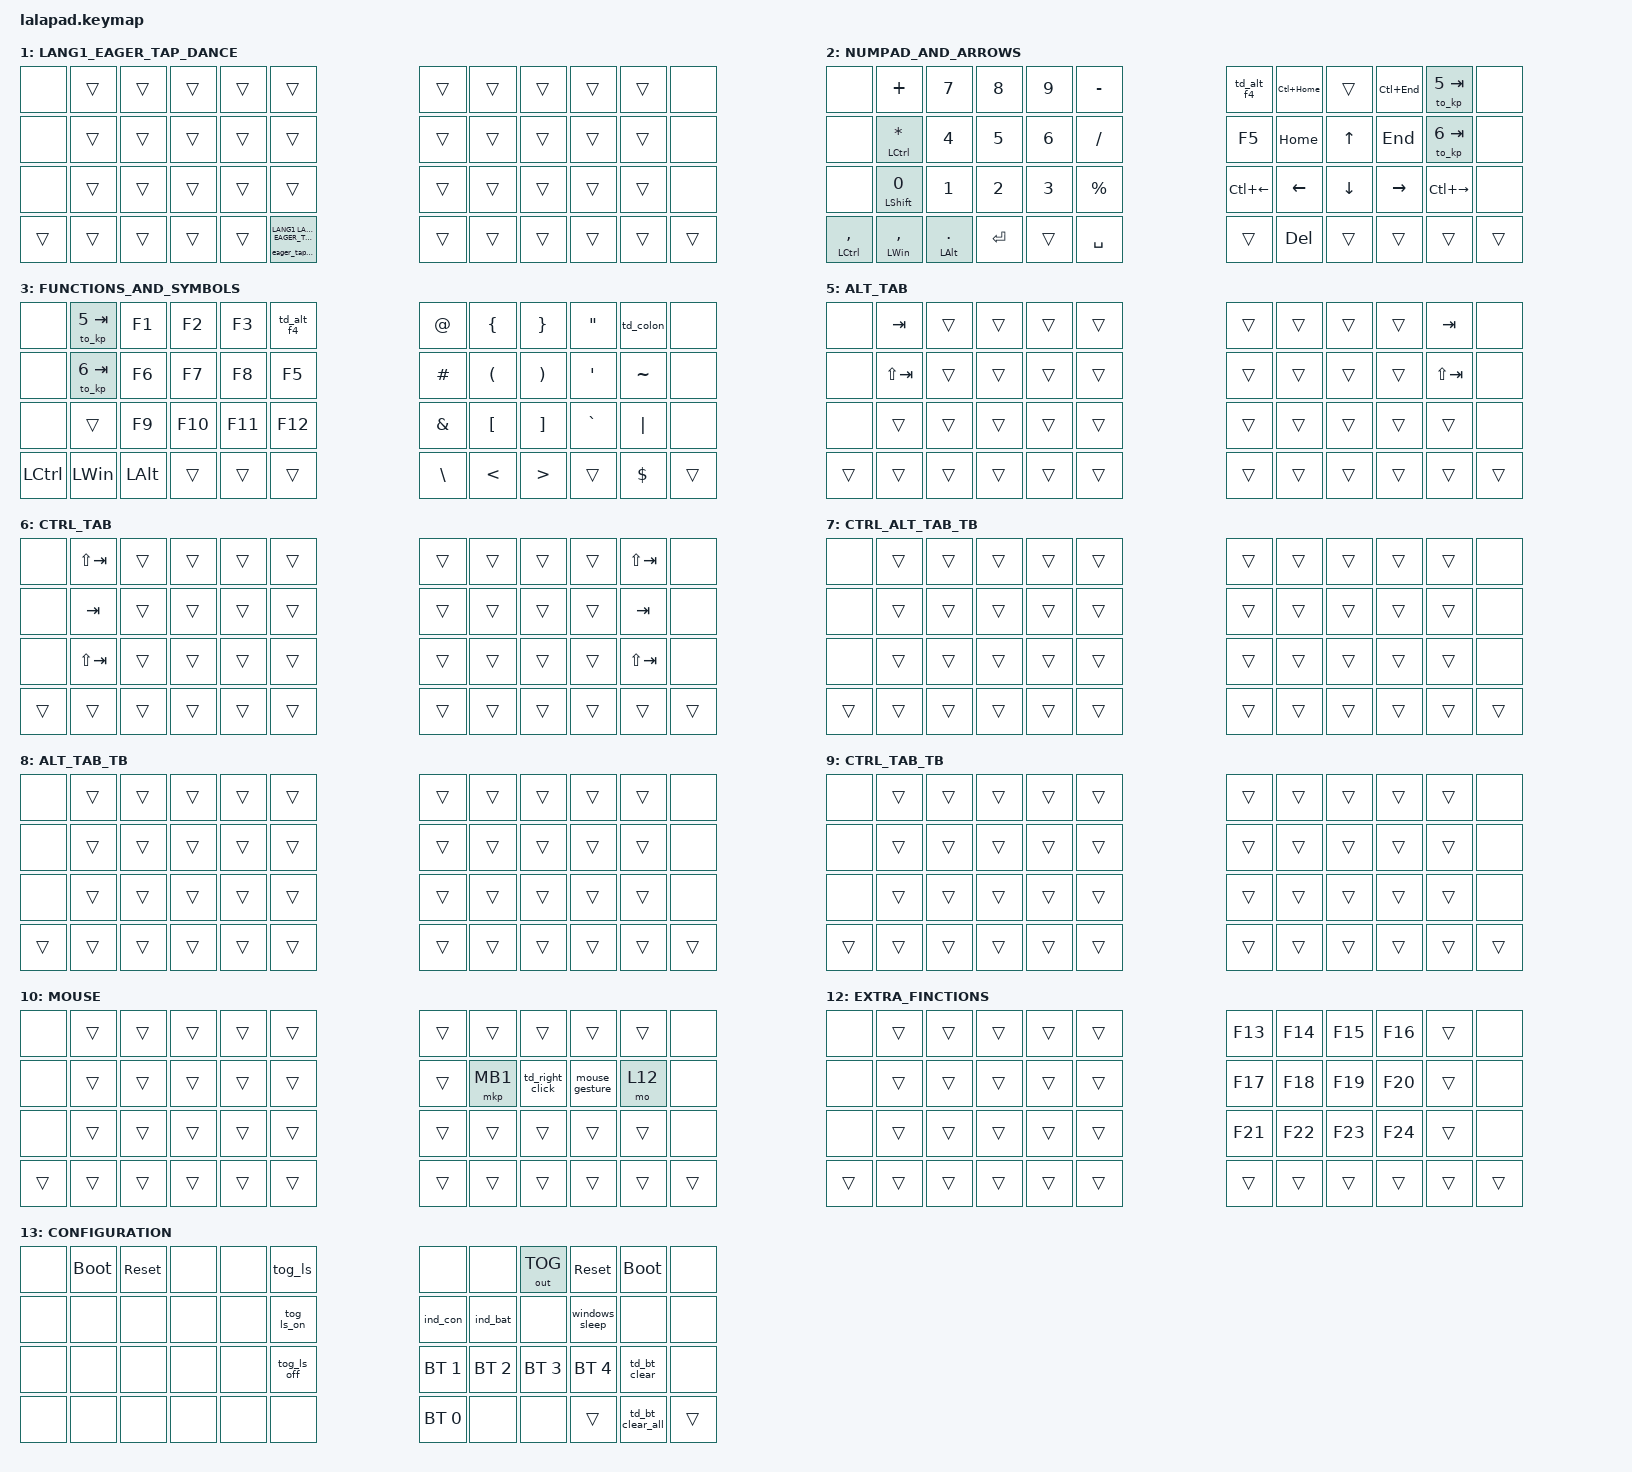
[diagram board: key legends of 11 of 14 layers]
#define ZMK_POINTING_DEFAULT_SCRL_VAL 1000

// #define ZMK_POINTING_DEFAULT_MOVE_VAL 700

#include <input/processors.dtsi>
#include <dt-bindings/zmk/input_transform.h>
#include <zephyr/dt-bindings/input/input-event-codes.h>
#include <behaviors/rgbled_widget.dtsi>
#include <input/processors/report_rate_limit.dtsi>
// #include <input/processors/sensor_rotation.dtsi>

#include <behaviors.dtsi>
#include <dt-bindings/zmk/bt.h>
#include <dt-bindings/zmk/keys.h>
#include <dt-bindings/zmk/outputs.h>
#include <dt-bindings/zmk/pointing.h>

// #include <layout_shift.dtsi>
#include <layout_shift_kp_override.dtsi>

#include <mouse-gesture.dtsi>

#define DEFAULT 0
#define LANG1_EAGER_TAP_DANCE 1
#define NUMPAD_AND_ARROWS 2
#define FUNCTIONS_AND_SYMBOLS 3
#define MISC 4
#define ALT_TAB 5
#define CTRL_TAB 6
#define CTRL_ALT_TAB_TB 7
#define ALT_TAB_TB 8
#define CTRL_TAB_TB 9
#define MOUSE 10
#define MEDIA 11
#define EXTRA_FINCTIONS 12
#define CONFIGURATION 13

&mt {
    tapping-term-ms = <200>;
    quick-tap-ms = <250>;
    flavor = "balanced";
};

&lt {
    tapping-term-ms = <200>;
    quick-tap-ms = <250>;
    flavor = "balanced";
};

&sk { release-after-ms = <700>; };

&sl { release-after-ms = <1000>; };

&zip_temp_layer {
    require-prior-idle-ms = <200>;
    excluded-positions = <
        18 // J
        19 // K
        20 // L
        21 // ;
        22 // Z
        // 31 // .
        // 32 // ,
        // 33 // /
        34 // Ctrl
        42
    >;
};

&mkp_input_listener { input-processors = <&zip_temp_layer MOUSE 10000>; };

&zip_mouse_gesture {
    stroke-size = <150>;
    enable-eager-mode;

    history_back {
        pattern = <GESTURE_RIGHT>;
        bindings = <&kp LA(LEFT)>;
    };

    history_forward {
        pattern = <GESTURE_LEFT>;
        bindings = <&kp LA(RIGHT)>;
    };

    close_tab {
        pattern = <GESTURE_DOWN GESTURE_RIGHT>;
        bindings = <&kp LC(W)>;
    };

    new_tab {
        pattern = <GESTURE_DOWN GESTURE_LEFT>;
        bindings = <&kp LC(T)>;
    };

    app_switcher {
        pattern = <GESTURE_DOWN GESTURE_UP>;
        bindings = <&kp LG(TAB)>;
    };

    virtual_desktop_prev {
        pattern = <GESTURE_LEFT GESTURE_DOWN>;
        bindings = <&kp LG(LC(LEFT))>;
    };

    virtual_desktop_next {
        pattern = <GESTURE_RIGHT GESTURE_DOWN>;
        bindings = <&kp LG(LC(RIGHT))>;
    };

    // left {
    //     gesture = <GESTURE_LEFT>;
    //     bindings = <&kp LEFT>;
    // };
    // right {
    //     gesture = <GESTURE_RIGHT>;
    //     bindings = <&kp RIGHT>;
    // };
    // up {
    //     gesture = <GESTURE_UP>;
    //     bindings = <&kp UP>;
    // };
    // down {
    //     gesture = <GESTURE_DOWN>;
    //     bindings = <&kp DOWN>;
    // };
};

// &sensor_rotation {
//     rotation-angle = <30>;
// };

// cirque trackpad input&layer control

&glidepoint_listener_R {
    input-processors =
        <&zip_report_rate_limit 15>,
        <&zip_xy_transform INPUT_TRANSFORM_X_INVERT>,
        // <&sensor_rotation>,
        <&zip_xy_scaler 4 1>,
        <&zip_mouse_gesture>,
        <&zip_temp_layer MOUSE 10000>;

    auto-mouse-layer {
        layers = <DEFAULT MOUSE>;
        input-processors = <&zip_temp_layer MOUSE 10000>;
        process-next;
    };

    scroller {
        layers = <FUNCTIONS_AND_SYMBOLS MISC EXTRA_FINCTIONS MEDIA>;
        input-processors =
            <&zip_xy_to_scroll_mapper>,
            <&zip_scroll_transform (INPUT_TRANSFORM_XY_SWAP | INPUT_TRANSFORM_Y_INVERT)>,
            <&zip_scroll_scaler 1 8>;
    };

    disable-scroll-x {
        layers = <MISC MEDIA>;
        input-processors = <&wheel_x_scaler 0 1>;
        process-next;
    };
};

/ {
    input_processors {
        wheel_x_scaler: wheel_x_scaler {
            compatible = "zmk,input-processor-scaler";
            #input-processor-cells = <2>;
            type = <INPUT_EV_REL>;
            codes = <INPUT_REL_HWHEEL>;
            track-remainders;
        };
    };

    layer_listeners {
        compatible = "zmk,layer-listeners";

        release_alt {
            layers = <ALT_TAB ALT_TAB_TB>;
            bindings = <&kt_on LEFT_ALT &kt_off LEFT_ALT>;
        };

        release_ctrl {
            layers = <CTRL_TAB CTRL_TAB_TB>;
            bindings = <&kt_on LCTRL &kt_off LCTRL>;
        };

        // AML_indicator {
        //     layers = <MOUSE>;
        //     bindings = <&kp LS(LA(LC(LG(H)))) &kp LS(LA(LC(LG(H))))>;
        // };
        // AML {
        //     layers = <MOUSE>;
        //     bindings = <&to MOUSE &none>;
        // };
    };

    combos {
        compatible = "zmk,combos";

        eq {
            bindings = <&kp EQUAL>;
            key-positions = <0 1>;
            layers = <2>;
        };

        hat {
            bindings = <&kp CARET>;
            key-positions = <10 11>;
            layers = <2>;
        };

        middle_click {
            bindings = <&mkp MCLK>;
            key-positions = <18 19>;
            layers = <10>;
        };

        shift_middle_click {
            bindings = <&mkp_with_mod LEFT_SHIFT MCLK>;
            key-positions = <19 20>;
            layers = <10>;
        };

        Escape {
            bindings = <&kp ESCAPE>;
            key-positions = <0 1>;
            layers = <0>;
            require-prior-idle-ms = <400>;
        };

        caps_word {
            bindings = <&caps_word>;
            key-positions = <22 33>;
            layers = <0>;
            require-prior-idle-ms = <400>;
        };

        dot_slash_backslash {
            bindings = <&kp BACKSLASH>;
            key-positions = <33 32>;
            layers = <0>;
            require-prior-idle-ms = <400>;
        };

        Ctrl_A {
            bindings = <&kp LC(A)>;
            key-positions = <10 11>;
            layers = <0>;
            require-prior-idle-ms = <400>;
        };

        Ctrl_W {
            bindings = <&kp LC(W)>;
            key-positions = <1 2>;
            layers = <0>;
            require-prior-idle-ms = <400>;
        };

        Ctrl_R {
            bindings = <&kp LC(R)>;
            key-positions = <2 3>;
            layers = <0>;
            require-prior-idle-ms = <400>;
        };

        Ctrl_T {
            bindings = <&kp LC(T)>;
            key-positions = <3 4>;
            layers = <0>;
            require-prior-idle-ms = <400>;
        };

        Ctrl_Z {
            bindings = <&kp LC(Z)>;
            key-positions = <23 22>;
            layers = <0>;
            require-prior-idle-ms = <400>;
        };

        Ctrl_X {
            bindings = <&kp LC(X)>;
            key-positions = <23 24>;
            layers = <0>;
            require-prior-idle-ms = <400>;
        };

        Ctrl_C {
            bindings = <&kp LC(C)>;
            key-positions = <24 25>;
            layers = <0>;
            require-prior-idle-ms = <400>;
        };

        Ctrl_V {
            bindings = <&kp LC(V)>;
            key-positions = <25 26>;
            layers = <0>;
            require-prior-idle-ms = <400>;
        };

        Ctrl_N {
            bindings = <&kp LC(N)>;
            key-positions = <29 30>;
            layers = <0>;
            require-prior-idle-ms = <400>;
        };

        Ctrl_S {
            bindings = <&kp LC(S)>;
            key-positions = <11 12>;
            layers = <0>;
            require-prior-idle-ms = <400>;
        };

        Ctrl_F {
            bindings = <&kp LC(F)>;
            key-positions = <13 14>;
            layers = <0>;
            require-prior-idle-ms = <400>;
        };
    };

    macros {
        /omit-if-no-ref/

        exit_AML: exit_AML {
            compatible = "zmk,behavior-macro";
            wait-ms = <0>;
            tap-ms = <0>;
            #binding-cells = <0>;
            bindings = <&tog_off 10>;
        };

        /omit-if-no-ref/

        kp_exit_AML: kp_exit_AML {
            compatible = "zmk,behavior-macro-one-param";
            wait-ms = <0>;
            tap-ms = <0>;
            #binding-cells = <1>;
            bindings = <&macro_param_1to1 &kp MACRO_PLACEHOLDER &exit_AML>;
        };

        /omit-if-no-ref/

        mod_exit_AML: mod_exit_AML {
            compatible = "zmk,behavior-macro-one-param";
            wait-ms = <0>;
            tap-ms = <0>;
            #binding-cells = <1>;
            bindings =
                <&macro_press>,
                <&macro_param_1to1 &kp MACRO_PLACEHOLDER>,
                <&macro_tap>,
                <&exit_AML>,
                <&macro_pause_for_release>,
                <&macro_release>,
                <&macro_param_1to1 &kp MACRO_PLACEHOLDER>;
        };

        /omit-if-no-ref/

        mkp_exit_AML: mkp_exit_AML {
            compatible = "zmk,behavior-macro-one-param";
            #binding-cells = <1>;
            bindings =
                <&macro_press>,
                <&macro_param_1to1 &mkp MACRO_PLACEHOLDER>,
                <&macro_pause_for_release>,
                <&macro_release>,
                <&macro_param_1to1 &mkp MACRO_PLACEHOLDER>,
                <&macro_tap>,
                <&sl 10>;
        };

        /omit-if-no-ref/

        mo_exit_AML: mo_exit_AML {
            compatible = "zmk,behavior-macro-one-param";
            wait-ms = <0>;
            tap-ms = <0>;
            #binding-cells = <1>;
            bindings =
                <&macro_press>,
                <&macro_param_1to1 &mo MACRO_PLACEHOLDER>,
                <&macro_tap>,
                <&exit_AML>,
                <&macro_pause_for_release>,
                <&macro_release>,
                <&macro_param_1to1 &mo MACRO_PLACEHOLDER>,
                <&macro_tap>;
        };

        /omit-if-no-ref/

        mo_exit_alttab: mo_exit_alttab_ctrltab {
            compatible = "zmk,behavior-macro-one-param";
            wait-ms = <0>;
            tap-ms = <0>;
            #binding-cells = <1>;
            bindings =
                <&macro_press>,
                <&macro_param_1to1 &mo MACRO_PLACEHOLDER>,
                <&macro_tap>,
                <&macro_pause_for_release>,
                <&macro_release>,
                <&macro_param_1to1 &mo MACRO_PLACEHOLDER>,
                <&macro_tap>,
                <&tog_off ALT_TAB &tog_off CTRL_TAB>;
        };

        /omit-if-no-ref/

        kp_to: kp_to {
            compatible = "zmk,behavior-macro-two-param";
            wait-ms = <0>;
            tap-ms = <0>;
            #binding-cells = <2>;
            bindings = <&macro_param_1to1 &kp MACRO_PLACEHOLDER &macro_param_2to1 &to MACRO_PLACEHOLDER>;
        };

        /omit-if-no-ref/

        to_kp: to_kp {
            compatible = "zmk,behavior-macro-two-param";
            #binding-cells = <2>;
            bindings = <&macro_param_1to1 &to MACRO_PLACEHOLDER &macro_param_2to1 &kp MACRO_PLACEHOLDER>;
        };

        /omit-if-no-ref/

        zoom_in: zoom_in {
            compatible = "zmk,behavior-macro";
            #binding-cells = <0>;
            bindings = <&kt_on LCTRL &msc SCRL_UP &kt_off LCTRL>;
        };

        /omit-if-no-ref/

        zoom_out: zoom_out {
            compatible = "zmk,behavior-macro";
            #binding-cells = <0>;
            bindings = <&kt_on LCTRL &msc SCRL_DOWN &kt_off LCTRL>;
        };

        /omit-if-no-ref/

        eager_tap_dance: eager_tap_dance {
            compatible = "zmk,behavior-macro-two-param";
            #binding-cells = <2>;
            bindings =
                <&macro_press>,
                <&macro_param_1to1 &kp MACRO_PLACEHOLDER>,
                <&macro_pause_for_release>,
                <&macro_release>,
                <&macro_param_1to1 &kp MACRO_PLACEHOLDER>,
                <&macro_tap>,
                <&exit_AML &macro_param_2to1 &sl_250 MACRO_PLACEHOLDER>;
        };
    };

    behaviors {
        /omit-if-no-ref/

        tog_on: toggle_layer_on {
            compatible = "zmk,behavior-toggle-layer";
            #binding-cells = <1>;
            display-name = "Toggle Layer On";
            toggle-mode = "on";
        };

        /omit-if-no-ref/

        tog_off: toggle_layer_off {
            compatible = "zmk,behavior-toggle-layer";
            #binding-cells = <1>;
            display-name = "Toggle Layer Off";
            toggle-mode = "off";
        };

        /omit-if-no-ref/

        kt_on: key_toggle_on_only {
            compatible = "zmk,behavior-key-toggle";
            #binding-cells = <1>;
            display-name = "Key Toggle On";
            toggle-mode = "on";
        };

        /omit-if-no-ref/

        kt_off: key_toggle_off_only {
            compatible = "zmk,behavior-key-toggle";
            #binding-cells = <1>;
            display-name = "Key Toggle Off";
            toggle-mode = "off";
        };

        /omit-if-no-ref/

        td_right_click: td_right_click {
            compatible = "zmk,behavior-tap-dance";
            #binding-cells = <0>;
            bindings = <&mkp RCLK>, <&kp LC(W)>;

            tapping-term-ms = <250>;
        };

        /omit-if-no-ref/

        td_colon: td_colon {
            compatible = "zmk,behavior-tap-dance";
            #binding-cells = <0>;
            bindings = <&kp COLON>, <&kp SEMICOLON>;

            tapping-term-ms = <250>;
        };

        /omit-if-no-ref/

        td_q_escape: td_q_escape {
            compatible = "zmk,behavior-tap-dance";
            #binding-cells = <0>;
            tapping-term-ms = <250>;
            bindings = <&kp Q>, <&kp ESCAPE>;
        };

        /omit-if-no-ref/

        td_ZenkakuHankaku: td_ZenkakuHankaku {
            compatible = "zmk,behavior-tap-dance";

            // compatible = "zmk,behavior-eager-tap-dance";

            #binding-cells = <0>;
            tapping-term-ms = <250>;
            bindings = <&kp LANGUAGE_2>, <&kp LANGUAGE_1>;
        };

        /omit-if-no-ref/

        td_ZenkakuHankaku_exit_AML: td_ZenkakuHankaku_exit_AML {
            wait-ms = <0>;
            tap-ms = <0>;
            compatible = "zmk,behavior-macro";
            #binding-cells = <0>;
            bindings = <&td_ZenkakuHankaku &exit_AML>;
        };

        /omit-if-no-ref/

        alt_tab: alt_tab {
            compatible = "zmk,behavior-macro-two-param";
            #binding-cells = <2>;
            bindings = <&macro_param_1to1 &kt_on MACRO_PLACEHOLDER &macro_param_2to1 &kp MACRO_PLACEHOLDER &macro_param_1to1 &sk MACRO_PLACEHOLDER &macro_param_1to1 &kt_off MACRO_PLACEHOLDER>;
        };

        /omit-if-no-ref/

        windows_sleep: windows_sleep {
            compatible = "zmk,behavior-macro";
            wait-ms = <200>;
            tap-ms = <100>;
            #binding-cells = <0>;
            bindings = <&kp LG(X) &kp U &kp S>;
        };

        /omit-if-no-ref/

        screensot_save: screensot_save {
            compatible = "zmk,behavior-macro";
            #binding-cells = <0>;
            bindings = <&kp LS(F11)>;
            label = "SCREENSOT_SAVE";
        };

        mkp_with_mod: mkp_with_mod {
            compatible = "zmk,behavior-macro-two-param";
            #binding-cells = <2>;
            bindings =
                <&macro_press>,
                <&macro_param_1to1 &kp MACRO_PLACEHOLDER &macro_param_2to1 &mkp MACRO_PLACEHOLDER>,
                <&macro_pause_for_release>,
                <&macro_release>,
                <&macro_param_2to1 &mkp MACRO_PLACEHOLDER &macro_param_1to1 &kp MACRO_PLACEHOLDER>;

            label = "MKP_WITH_MOD";
        };

        /omit-if-no-ref/

        screenshot_copy: screenshot_copy {
            compatible = "zmk,behavior-mod-morph";
            bindings = <&kp LA(PRINTSCREEN)>, <&kp LA(PRINTSCREEN)>;

            #binding-cells = <0>;
            mods = <(MOD_LSFT|MOD_LALT)>;
            keep-mods = <(MOD_LALT)>;
        };

        /omit-if-no-ref/

        mod_morph_exclamation: mod_morph_exclamation {
            compatible = "zmk,behavior-mod-morph";
            bindings = <&kp COMMA>, <&kp EXCL>;

            #binding-cells = <0>;
            mods = <(MOD_LSFT)>;
        };

        /omit-if-no-ref/

        mod_morph_question: mod_morph_question {
            compatible = "zmk,behavior-mod-morph";
            bindings = <&kp PERIOD>, <&kp QUESTION>;

            #binding-cells = <0>;
            mods = <(MOD_LSFT)>;
        };

        /omit-if-no-ref/

        mod_morph_slash: mod_morph_slash {
            compatible = "zmk,behavior-mod-morph";
            bindings = <&kp SLASH>, <&kp BACKSLASH>;

            #binding-cells = <0>;
            mods = <(MOD_LSFT)>;
        };

        /omit-if-no-ref/

        td_alt_f4: td_alt_f4 {
            compatible = "zmk,behavior-tap-dance";
            #binding-cells = <0>;
            bindings = <&kp F4>, <&kp LA(F4)>;

            tapping-term-ms = <250>;
        };

        /omit-if-no-ref/

        lt_exit_AML: lt_exit_AML {
            compatible = "zmk,behavior-hold-tap";
            bindings = <&mo_exit_AML>, <&kp_exit_AML>;

            #binding-cells = <2>;
            tapping-term-ms = <200>;
            quick-tap-ms = <200>;
            flavor = "balanced";
        };

        /omit-if-no-ref/

        lt_exit_AML_on_hold: lt_exit_AML_on_hold {
            compatible = "zmk,behavior-hold-tap";
            bindings = <&mo_exit_AML>, <&kp>;

            #binding-cells = <2>;
            tapping-term-ms = <200>;
            quick-tap-ms = <200>;
            flavor = "balanced";
        };

        /omit-if-no-ref/

        lt_exit_alttab: lt_exit_alttab_ctrltab_on_hold_release {
            compatible = "zmk,behavior-hold-tap";
            bindings = <&mo_exit_alttab>, <&kp>;

            #binding-cells = <2>;
            tapping-term-ms = <200>;
            quick-tap-ms = <200>;
            flavor = "balanced";
        };

        /omit-if-no-ref/

        mt_exit_AML: mt_exit_AML {
            compatible = "zmk,behavior-hold-tap";
            bindings = <&mod_exit_AML>, <&kp_exit_AML>;

            #binding-cells = <2>;
            tapping-term-ms = <200>;
            flavor = "balanced";
            quick-tap-ms = <200>;
        };

        /omit-if-no-ref/

        mt_exit_AML_on_tap: mt_exit_AML_on_tap {
            compatible = "zmk,behavior-hold-tap";
            bindings = <&kp>, <&kp_exit_AML>;

            #binding-cells = <2>;
            tapping-term-ms = <200>;
            flavor = "balanced";
            quick-tap-ms = <200>;
        };

        /omit-if-no-ref/

        encoder_zoom: encoder_zoom {
            compatible = "zmk,behavior-sensor-rotate";
            #sensor-binding-cells = <0>;
            bindings = <&zoom_out>, <&zoom_in>;
        };

        /omit-if-no-ref/

        encoder_volume: encoder_volume {
            compatible = "zmk,behavior-sensor-rotate";
            #sensor-binding-cells = <0>;
            bindings = <&kp C_VOLUME_DOWN>, <&kp C_VOLUME_UP>;
        };

        /omit-if-no-ref/

        sl_250: sl_250 {
            compatible = "zmk,behavior-sticky-key";
            bindings = <&mo>;
            #binding-cells = <1>;
            release-after-ms = <250>;
        };

        /omit-if-no-ref/

        td_bt_clear: td_bt_clear {
            compatible = "zmk,behavior-tap-dance";
            #binding-cells = <0>;
            bindings = <&none>, <&none>, <&bt BT_CLR>;

            tapping-term-ms = <250>;
        };

        /omit-if-no-ref/

        td_bt_clear_all: td_bt_clear_all {
            compatible = "zmk,behavior-tap-dance";
            #binding-cells = <0>;
            tapping-term-ms = <250>;
            bindings = <&none>, <&none>, <&bt BT_CLR_ALL>;
        };

        /omit-if-no-ref/

        td_copy_paste: td_copy_paste {
            compatible = "zmk,behavior-tap-dance";
            #binding-cells = <0>;
            bindings = <&kp_exit_AML LC(C)>, <&kp_exit_AML LC(V)>;

            tapping-term-ms = <250>;
        };
    };

    keymap {
        compatible = "zmk,keymap";

        DEFAULT {
            bindings = <
&none      &mt LWIN Q                        &kp W             &kp E                    &kp R                  &lt 13 T                       &lt 13 Y  &kp U                        &kp I                    &kp O                &lt 11 P              &none
&none      &mt LCTRL A                       &kp S             &kp D                    &kp F                  &kp G                          &kp H     &kp J                        &kp K                    &kp L                &lt 12 MINUS          &none
&none      &mt_exit_AML_on_tap LEFT_SHIFT Z  &mt LEFT_SHIFT X  &kp C                    &kp V                  &kp B                          &kp N     &kp M                        &mod_morph_exclamation   &mod_morph_question  &mt LEFT_SHIFT SLASH  &none
&kp LCTRL  &kp LEFT_WIN                      &kp LEFT_ALT      &lt_exit_alttab 3 SPACE  &lt_exit_alttab 4 TAB  &eager_tap_dance LANGUAGE_2 1  &none     &lt_exit_alttab 4 BACKSPACE  &lt_exit_alttab 2 ENTER  &none                &lt 12 ESCAPE         &none
&kp RIGHT &kp DOWN &kp LEFT &kp UP
            >;
        };

        LANG1_EAGER_TAP_DANCE {
            bindings = <
&none   &trans  &trans  &trans  &trans  &trans                                        &trans  &trans  &trans  &trans  &trans  &none
&none   &trans  &trans  &trans  &trans  &trans                                        &trans  &trans  &trans  &trans  &trans  &none
&none   &trans  &trans  &trans  &trans  &trans                                        &trans  &trans  &trans  &trans  &trans  &none
&trans  &trans  &trans  &trans  &trans  &eager_tap_dance LANG1 LANG1_EAGER_TAP_DANCE  &trans  &trans  &trans  &trans  &trans  &trans
            >;
        };

        NUMPAD_AND_ARROWS {
            bindings = <
&none            &kp PLUS                   &kp N7               &kp N8     &kp N9  &kp MINUS    &td_alt_f4    &kp LC(HOME)  &trans        &kp LC(END)  &to_kp 5 TAB   &none
&none            &mt LEFT_CONTROL ASTERISK  &kp N4               &kp N5     &kp N6  &kp SLASH    &kp F5        &kp HOME      &kp UP_ARROW  &kp END      &to_kp 6 TAB   &none
&none            &mt LEFT_SHIFT N0          &kp N1               &kp N2     &kp N3  &kp PERCENT  &kp LC(LEFT)  &kp LEFT      &kp DOWN      &kp RIGHT    &kp LC(RIGHT)  &none
&mt LCTRL COMMA  &mt LEFT_WIN COMMA         &mt LEFT_ALT PERIOD  &kp ENTER  &trans  &kp SPACE    &trans        &kp DELETE    &trans        &trans       &trans         &trans
            >;

            sensor-bindings = <&inc_dec_kp LC(PLUS) LC(MINUS)>;
        };

        FUNCTIONS_AND_SYMBOLS {
            bindings = <
&none      &to_kp 5 TAB  &kp F1        &kp F2   &kp F3   &td_alt_f4  &kp AT_SIGN    &kp LEFT_BRACE        &kp RIGHT_BRACE        &kp DOUBLE_QUOTES  &td_colon   &none
&none      &to_kp 6 TAB  &kp F6        &kp F7   &kp F8   &kp F5      &kp HASH       &kp LEFT_PARENTHESIS  &kp RIGHT_PARENTHESIS  &kp SINGLE_QUOTE   &kp TILDE   &none
&none      &trans        &kp F9        &kp F10  &kp F11  &kp F12     &kp AMPERSAND  &kp LEFT_BRACKET      &kp RIGHT_BRACKET      &kp GRAVE          &kp PIPE    &none
&kp LCTRL  &kp LEFT_WIN  &kp LEFT_ALT  &trans   &trans   &trans      &kp BSLH       &kp LESS_THAN         &kp GREATER_THAN       &trans             &kp DOLLAR  &trans
            >;
        };

        MISC {
            bindings = <
&none   &to_kp 5 TAB          &kp LC(LG(LEFT))        &kp LG(TAB)       &kp LG(LC(RIGHT))        &td_alt_f4        &td_alt_f4                  &kp LC(W)                 &kp LS(LC(T))          &kp LC(T)          &to_kp 5 TAB  &none
&none   &to_kp 6 TAB          &kp LG(LS(LEFT_ARROW))  &kp LG(UP_ARROW)  &kp LG(LS(RIGHT_ARROW))  &kp F5            &kp F5                      &kp_exit_AML LC(PAGE_UP)  &kp_exit_AML UP_ARROW  &kp LC(PAGE_DOWN)  &to_kp 6 TAB  &none
&none   &kp LA(LC(LG(DOWN)))  &kp LG(LEFT_ARROW)      &kp LG(DOWN)      &kp LG(RIGHT_ARROW)      &screenshot_copy  &kp K_MUTE                  &kp LA(LEFT)              &kp DOWN               &kp LA(RIGHT)      &trans        &none
&trans  &trans                &trans                  &trans            &trans                   &screensot_save   &kp_exit_AML C_VOLUME_DOWN  &kp DELETE                &trans                 &trans             &trans        &trans
            >;

            sensor-bindings = <&inc_dec_kp LC(PAGE_UP) LC(PAGE_DOWN)>;
        };

        ALT_TAB {
            bindings = <
&none   &kp TAB      &trans  &trans  &trans  &trans  &trans  &trans  &trans  &trans  &kp TAB      &none
&none   &kp LS(TAB)  &trans  &trans  &trans  &trans  &trans  &trans  &trans  &trans  &kp LS(TAB)  &none
&none   &trans       &trans  &trans  &trans  &trans  &trans  &trans  &trans  &trans  &trans       &none
&trans  &trans       &trans  &trans  &trans  &trans  &trans  &trans  &trans  &trans  &trans       &trans
            >;
        };

        CTRL_TAB {
            bindings = <
&none   &kp LS(TAB)  &trans  &trans  &trans  &trans  &trans  &trans  &trans  &trans  &kp LS(TAB)  &none
&none   &kp TAB      &trans  &trans  &trans  &trans  &trans  &trans  &trans  &trans  &kp TAB      &none
&none   &kp LS(TAB)  &trans  &trans  &trans  &trans  &trans  &trans  &trans  &trans  &kp LS(TAB)  &none
&trans  &trans       &trans  &trans  &trans  &trans  &trans  &trans  &trans  &trans  &trans       &trans
            >;
        };

        CTRL_ALT_TAB_TB {
            bindings = <
&none   &trans  &trans  &trans  &trans  &trans  &trans  &trans  &trans  &trans  &trans  &none
&none   &trans  &trans  &trans  &trans  &trans  &trans  &trans  &trans  &trans  &trans  &none
&none   &trans  &trans  &trans  &trans  &trans  &trans  &trans  &trans  &trans  &trans  &none
&trans  &trans  &trans  &trans  &trans  &trans  &trans  &trans  &trans  &trans  &trans  &trans
            >;
        };

        ALT_TAB_TB {
            bindings = <
&none   &trans  &trans  &trans  &trans  &trans  &trans  &trans  &trans  &trans  &trans  &none
&none   &trans  &trans  &trans  &trans  &trans  &trans  &trans  &trans  &trans  &trans  &none
&none   &trans  &trans  &trans  &trans  &trans  &trans  &trans  &trans  &trans  &trans  &none
&trans  &trans  &trans  &trans  &trans  &trans  &trans  &trans  &trans  &trans  &trans  &trans
            >;
        };

        CTRL_TAB_TB {
            bindings = <
&none   &trans  &trans  &trans  &trans  &trans  &trans  &trans  &trans  &trans  &trans  &none
&none   &trans  &trans  &trans  &trans  &trans  &trans  &trans  &trans  &trans  &trans  &none
&none   &trans  &trans  &trans  &trans  &trans  &trans  &trans  &trans  &trans  &trans  &none
&trans  &trans  &trans  &trans  &trans  &trans  &trans  &trans  &trans  &trans  &trans  &trans
            >;
        };

        MOUSE {
            bindings = <
&none   &trans  &trans  &trans  &trans  &trans  &trans  &trans    &trans           &trans          &trans  &none
&none   &trans  &trans  &trans  &trans  &trans  &trans  &mkp MB1  &td_right_click  &mouse_gesture  &mo 12  &none
&none   &trans  &trans  &trans  &trans  &trans  &trans  &trans    &trans           &trans          &trans  &none
&trans  &trans  &trans  &trans  &trans  &trans  &trans  &trans    &trans           &trans          &trans  &trans
            >;
        };

        MEDIA {
            bindings = <
&none   &trans  &trans  &trans  &trans  &trans  &kp C_PREV         &kp C_PLAY_PAUSE   &kp C_NEXT       &trans  &trans  &none
&none   &trans  &trans  &trans  &trans  &trans  &kp C_VOLUME_DOWN  &kp C_MUTE         &kp C_VOLUME_UP  &trans  &trans  &none
&none   &trans  &trans  &trans  &trans  &trans  &trans             &kp LS(LA(LC(M)))  &trans           &trans  &trans  &none
&trans  &trans  &trans  &trans  &trans  &trans  &trans             &trans             &trans           &trans  &trans  &trans
            >;
        };

        EXTRA_FINCTIONS {
            bindings = <
&none   &trans  &trans  &trans  &trans  &trans  &kp F13  &kp F14  &kp F15  &kp F16  &trans  &none
&none   &trans  &trans  &trans  &trans  &trans  &kp F17  &kp F18  &kp F19  &kp F20  &trans  &none
&none   &trans  &trans  &trans  &trans  &trans  &kp F21  &kp F22  &kp F23  &kp F24  &trans  &none
&trans  &trans  &trans  &trans  &trans  &trans  &trans   &trans   &trans   &trans   &trans  &trans
            >;
        };

        CONFIGURATION {
            bindings = <
&none  &bootloader  &sys_reset  &none  &none  &tog_ls      &none         &none         &out OUT_TOG  &sys_reset      &bootloader       &none
&none  &none        &none       &none  &none  &tog_ls_on   &ind_con      &ind_bat      &none         &windows_sleep  &none             &none
&none  &none        &none       &none  &none  &tog_ls_off  &bt BT_SEL 1  &bt BT_SEL 2  &bt BT_SEL 3  &bt BT_SEL 4    &td_bt_clear      &none
&none  &none        &none       &none  &none  &none        &bt BT_SEL 0  &none         &none         &trans          &td_bt_clear_all  &trans
            >;
        };
    };
};
